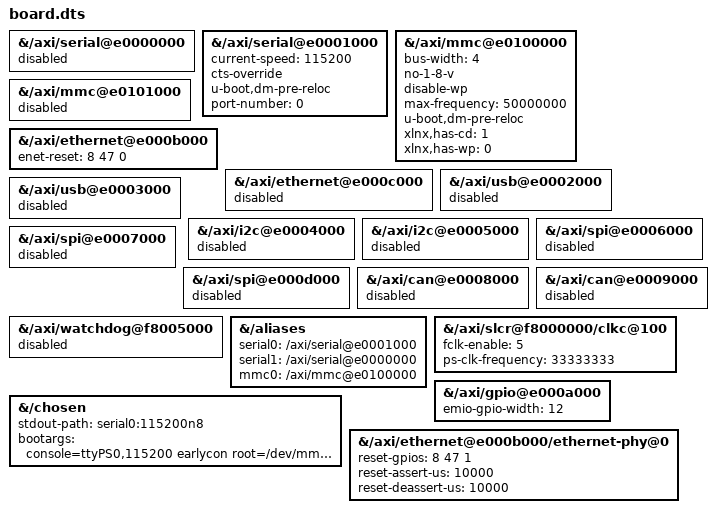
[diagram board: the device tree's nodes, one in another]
/include/ "base.dts"
&{/axi/serial@e0000000} { status = "disabled"; };
&{/axi/serial@e0001000} { status = "okay"; };
&{/axi/mmc@e0100000} { status = "okay"; };
&{/axi/mmc@e0101000} { status = "disabled"; };
&{/axi/ethernet@e000b000} { status = "okay"; };
&{/axi/ethernet@e000c000} { status = "disabled"; };
&{/axi/usb@e0002000} { status = "disabled"; };
&{/axi/usb@e0003000} { status = "disabled"; };
&{/axi/i2c@e0004000} { status = "disabled"; };
&{/axi/i2c@e0005000} { status = "disabled"; };
&{/axi/spi@e0006000} { status = "disabled"; };
&{/axi/spi@e0007000} { status = "disabled"; };
&{/axi/spi@e000d000} { status = "disabled"; };
&{/axi/can@e0008000} { status = "disabled"; };
&{/axi/can@e0009000} { status = "disabled"; };
&{/axi/watchdog@f8005000} { status = "disabled"; };
&{/axi/serial@e0001000} { current-speed = <115200>; };
&{/axi/serial@e0001000} { cts-override; };
&{/aliases} { serial0 = "/axi/serial@e0001000"; serial1 = "/axi/serial@e0000000"; mmc0 = "/axi/mmc@e0100000"; };
&{/axi/serial@e0001000} { u-boot,dm-pre-reloc; port-number = <0>; };
&{/chosen} { stdout-path = "serial0:115200n8"; bootargs = "console=ttyPS0,115200 earlycon root=/dev/mmcblk0p2 rw rootfstype=ext4 rootwait devtmpfs.mount=1 uio_pdrv_genirq.of_id=generic-uio clk_ignore_unused"; };
&{/axi/slcr@f8000000/clkc@100} { fclk-enable = <5>; ps-clk-frequency = <33333333>; };
&{/axi/gpio@e000a000} { emio-gpio-width = <12>; /delete-property/ gpio-mask-high; /delete-property/ gpio-mask-low; };
&{/axi/mmc@e0100000} { bus-width = <4>; no-1-8-v; disable-wp; max-frequency = <50000000>; u-boot,dm-pre-reloc; };
&{/axi/mmc@e0100000} { xlnx,has-cd = <1>; xlnx,has-wp = <0>; /delete-property/ broken-cd; };
&{/axi/ethernet@e000b000} { enet-reset = <8 47 0>; };
&{/axi/ethernet@e000b000/ethernet-phy@0} { reset-gpios = <8 47 1>; reset-assert-us = <10000>; reset-deassert-us = <10000>; };
